# LPC43xx register map
File version: 10
CPU: CM4 r0p0, little endian, no MPU, no FPU, 3 interrupt priority bits
Registers are 32-bit, read-write, reset 0x0 unless marked. A register's access mark holds for its fields unless they carry their own. Offsets are from the block's base; [hi:lo] are bit positions; {n}, {i} and the like mark numbered series.

## SGPIO — Serial GPIO (SGPIO)
Base 0x40101000
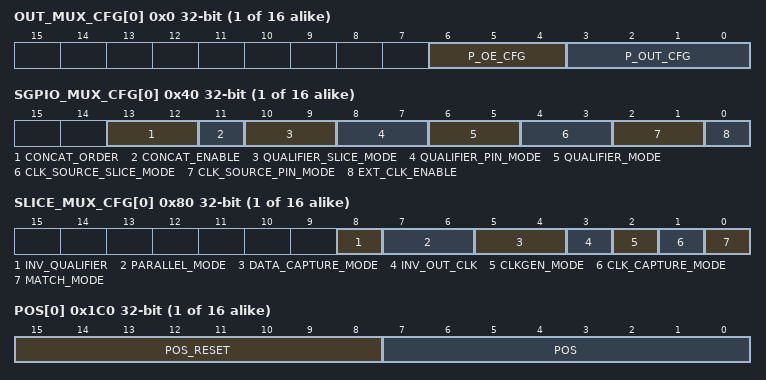
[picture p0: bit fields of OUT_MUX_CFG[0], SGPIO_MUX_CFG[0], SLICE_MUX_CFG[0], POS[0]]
{0x0+4i} OUT_MUX_CFG[{i}] (i=0..15) — Pin multiplexer configuration registers.
  [6:4] P_OE_CFG — Output enable source. All other values are reserved.
    0=GPIO_OE_STATE_SET_B (gpio_oe (state set by GPIO_OEREG)); 4=DOUT_OEM1_1_BIT_MOD (dout_oem1 (1-bit mode)); 5=DOUT_OEM2_2_BIT_MOD (dout_oem2 (2-bit mode)); 6=DOUT_OEM4_4_BIT_MOD (dout_oem4 (4-bit mode)); 7=DOUT_OEM8_8_BIT_MOD (dout_oem8 (8-bit mode))
  [3:0] P_OUT_CFG — Output control of output SGPIOn. All other values are reserved.
    0=DOUT_DOUTM1 (dout_doutm1 (1-bit mode)); 1=DOUT_DOUTM2A (dout_doutm2a (2-bit mode 2a)); 2=DOUT_DOUTM2B (dout_doutm2b (2-bit mode 2b)); 3=DOUT_DOUTM2C (dout_doutm2c (2-bit mode 2c)); 4=GPIO_OUT_LEVEL_SET (gpio_out (level set by GPIO_OUTREG)); 5=DOUT_DOUTM4A (dout_doutm4a (4-bit mode 4a)); 6=DOUT_DOUTM4B (dout_doutm4b (4-bit mode 4b)); 7=DOUT_DOUTM4C (dout_doutm4c (4-bit mode 4c)); 8=CLK_OUT; 9=DOUT_DOUTM8A (dout_doutm8a (8-bit mode 8a)); 10=DOUT_DOUTM8B (dout_doutm8b (8-bit mode 8b)); 11=DOUT_DOUTM8C (dout_doutm8c (8-bit mode 8c))
{0x40+4i} SGPIO_MUX_CFG[{i}] (i=0..15) — SGPIO multiplexer configuration registers.
  [13:12] CONCAT_ORDER — Select concatenation order
    0=SELF_LOOP; 1=2_SLICES; 2=4_SLICES; 3=8_SLICES
  [11] CONCAT_ENABLE — Enable concatenation.
    0=EXTERNAL_DATA_PIN; 1=CONCATENATE_DATA
  [10:9] QUALIFIER_SLICE_MODE — Select qualifier slice.
    0=SLICE_A (Slice A, but for slice A slice D is used.); 1=SLICE_H (Slice H, but for slice H slice O is used.); 2=SLICE_I (Slice I, but for slice I slice D is used.); 3=SLICE_P (Slice P, but for slice P slice O is used.)
  [8:7] QUALIFIER_PIN_MODE — Select qualifier pin.
    {v}=SGPIO{v+8} (v=0..3)
  [6:5] QUALIFIER_MODE — Select qualifier mode.
    0=ENABLE; 1=DISABLE; 2=SLICE_SEE_BITS_QUAL (Slice (see bits QUALIFIER_SLICE_MODE in this register)); 3=EXTERNAL_SGPIO_PIN (External SGPIO pin (SGPIO8, SGPIO9, SGPIO10, or SGPIO11))
  [4:3] CLK_SOURCE_SLICE_MODE — Select clock source slice. Note that slices D, H, O and P do not support this mode.
    0=SLICE_D; 1=SLICE_H; 2=SLICE_O; 3=SLICE_P
  [2:1] CLK_SOURCE_PIN_MODE — Select source clock pin.
    {v}=SGPIO{v+8} (v=0..3)
  [0] EXT_CLK_ENABLE — Select clock signal.
    0=INTERNAL_CLOCK_SIGNA (Internal clock signal (slice)); 1=EXTERNAL_CLOCK_SIGNA (External clock signal (pin))
{0x80+4i} SLICE_MUX_CFG[{i}] (i=0..15) — Slice multiplexer configuration registers.
  [8] INV_QUALIFIER — Inversion qualifier
    0=USE_NORMAL_QUALIFIER; 1=USE_INVERTED_QUALIFI (Use inverted qualifier.)
  [7:6] PARALLEL_MODE
    0=SHIFT_1_BIT_PER_CLOC (Shift 1 bit per clock.); 1=SHIFT_2_BITS_PER_CLO (Shift 2 bits per clock.); 2=SHIFT_4_BITS_PER_CLO (Shift 4 bits per clock.); 3=SHIFT_1_BYTE_PER_CLO (Shift 1 byte per clock.)
  [5:4] DATA_CAPTURE_MODE — Condition for input bit match interrupt
    0=DETECT_RISING_EDGE; 1=DETECT_FALLING_EDGE; 2=DETECT_LOW_LEVEL; 3=DETECT_HIGH_LEVEL
  [3] INV_OUT_CLK — Invert output clock
    0=NORMAL_CLOCK; 1=INVERTED_CLOCK
  [2] CLKGEN_MODE — Clock generation mode. Selects the clock generated by the slice counter or by an external pin or other slice as shift clock.
    0=USE_CLOCK_INTERNALLY (Use clock internally generated by COUNTER.); 1=USE_EXTERNAL_CLOCK_F (Use external clock from a pin or other slice.)
  [1] CLK_CAPTURE_MODE — Capture clock mode
    0=USE_RISING_CLOCK_EDG (Use rising clock edge.); 1=USE_FALLING_CLOCK_ED (Use falling clock edge.)
  [0] MATCH_MODE — Match mode. Selects whether the match filter is active or whether data is captured.
    0=DO_NOT_MATCH_DATA; 1=MATCH_DATA
{0xC0+4i} REG[{i}] (i=0..15) — Slice data registers. Each time COUNT0 reaches 0x0 the register shifts loading bit 31 with data captured from DIN(n). DOUT(n) is set to REG(0)
  [31:0] REG — At each active shift clock the register shifts right; loading REG(31) with data captured from DIN(n) and DOUT(n) is set to REG(0).
{0x100+4i} REG_SS[{i}] (i=0..15) — Slice data shadow registers. Each time POS reaches 0x0 the contents of REG_SS is exchanged with the content of REG
  [31:0] REG_SS — Each time POS reaches 0x0 the contents of REG_SS is exchanged with the content of REG.
{0x140+4i} PRESET[{i}] (i=0..15) — Reload value of COUNT0, loaded when COUNT0 reaches 0x0
  [11:0] PRESET — Counter reload value; loaded when COUNT reaches 0x0.
{0x180+4i} COUNT[{i}] (i=0..15) — Down counter, counts down each clock cycle.
  [11:0] COUNT — Down counter, counts down each shift clock cycle. Next count after 0x0 is PRESET.
{0x1C0+4i} POS[{i}] (i=0..15) — Each time COUNT0 reaches 0x0 POS counts down.
  [15:8] POS_RESET — Reload value for POS after POS reaches 0x0.
  [7:0] POS — Each time COUNT reaches 0x0 POS counts down.
0x200 MASK_A — Mask for pattern match function of slice A
  [31:0] MASK_A — Mask for pattern match function of slice A 0 = No effect. 1 = Mask this bit.
0x204 MASK_H — Mask for pattern match function of slice H
  [31:0] MASK_H — Mask for pattern match function of slice H 0 = No effect. 1 = Mask this bit.
0x208 MASK_I — Mask for pattern match function of slice I
  [31:0] MASK_I — Mask for pattern match function of slice I 0 = No effect . 1 = Mask this bit.
0x20C MASK_P — Mask for pattern match function of slice P
  [31:0] MASK_P — Mask for pattern match function of slice P 0 = No effect. 1 = Mask this bit.
0x210 GPIO_INREG ro — GPIO input status register
  [15:0] GPIO_INi — Bit i reflects the input state of SGPIO pin i . 0 = LOW 1 = HIGH
0x214 GPIO_OUTREG — GPIO output control register
  [15:0] GPIO_OUT — GPIO output register. Bit i sets the output of SGPIO pin i. 0 = LOW 1 = HIGH
0x218 GPIO_OENREG — GPIO OE control register
  [15:0] GPIO_OE — Bit i selects the output enable state of SGPIO pin i. 0 = GPIO output i is tri-stated . 1 = GPIO output i is active.
0x21C CTRL_ENABLE — Enables the slice COUNT counter
  [15:0] CTRL_EN — Slice count enable. Bit n controls slice n (0 = slice A, ..., 15 = slice P). 0 = Disables slice shift clock. 1 = Starts COUNTn or external shift clock.
0x220 CTRL_DISABLE — Disables the slice POS counter
  [15:0] CTRL_DIS — Slice count disable. Bit n controls slice n, (0 = slice A, ..., 15 = slice P). 0 = Enables COUNT and POS counters. The counters start counting when the CTRL_EN bit or bits are set in the CTRL_ENABLED register. 1 = Disables POS counter of slice n.
0xF00 CLR_EN_0 wo — Shift clock interrupt clear mask
  [15:0] CLR_SCI — 1 = Shift clock interrupt clear mask of slice n.
0xF04 SET_EN_0 wo — Shift clock interrupt set mask
  [15:0] SET_SCI — 1 = Shift clock interrupt set mask of slice n.
0xF08 ENABLE_0 ro — Shift clock interrupt enable
  [15:0] ENABLE_SCI — 1 = Shift clock interrupt enable of slice n.
0xF0C STATUS_0 ro — Shift clock interrupt status
  [15:0] STATUS_SCI — Shift clock interrupt status of slice n.
0xF10 CLR_STATUS_0 wo — Shift clock interrupt clear status
  [15:0] CLR_STATUS_SCI — Shift clock interrupt clear status of slice n.
0xF14 SET_STATUS_0 wo — Shift clock interrupt set status
  [15:0] SET_STATUS_SCI — Shift clock interrupt set status of slice n.
0xF20 CLR_EN_1 wo — Exchange clock interrupt clear mask
  [15:0] CLR_EN_CCI — 1 = Exchange clock interrupt clear mask of slice n.
0xF24 SET_EN_1 wo — Exchange clock interrupt set mask
  [15:0] SET_EN_CCI — 1 = Exchange clock interrupt set mask of slice n.
0xF28 ENABLE_1 ro — Exchange clock interrupt enable
  [15:0] ENABLE_CCI — Exchange clock interrupt enable of slice n.
0xF2C STATUS_1 ro — Exchange clock interrupt status
  [15:0] STATUS_CCI — Exchange clock interrupt status of slice n.
0xF30 CLR_STATUS_1 wo — Exchange clock interrupt clear status
  [15:0] CLR_STATUS_CCI — Exchange clock interrupt clear status of slice n.
0xF34 SET_STATUS_1 wo — Exchange clock interrupt set status
  [15:0] SET_STATUS_CCI — Exchange clock interrupt set status of slice n.
0xF40 CLR_EN_2 wo — Pattern match interrupt clear mask
  [15:0] CLR_EN2_PMI — 1 = Match interrupt clear mask of slice n.
0xF44 SET_EN_2 wo — Pattern match interrupt set mask
  [15:0] SET_EN_PMI — 1 = Match interrupt set mask of slice n.
0xF48 ENABLE_2 ro — Pattern match interrupt enable
  [15:0] ENABLE_PMI — Match interrupt enable of slice n.
0xF4C STATUS_2 ro — Pattern match interrupt status
  [15:0] STATUS_PMI — Match interrupt status of slice n.
0xF50 CLR_STATUS_2 wo — Pattern match interrupt clear status
  [15:0] CLR_STATUS_PMI — Match interrupt clear status of slice n.
0xF54 SET_STATUS_2 wo — Pattern match interrupt set status
  [15:0] SET_STATUS_PMI — Match interrupt set status of slice n.
0xF60 CLR_EN_3 wo — Input interrupt clear mask
  [15:0] CLR_EN_INPI — 1 = Input interrupt clear mask of slice n.
0xF64 SET_EN_3 wo — Input bit match interrupt set mask
  [15:0] SET_EN_INPI — 1 = Input interrupt set mask of slice n.
0xF68 ENABLE_3 ro — Input bit match interrupt enable
  [15:0] ENABLE3_INPI — Input interrupt enable of slice n.
0xF6C STATUS_3 ro — Input bit match interrupt status
  [15:0] STATUS_INPI — Input interrupt status of slice n.
0xF70 CLR_STATUS_3 wo — Input bit match interrupt clear status
  [15:0] CLR_STATUS_INPI — Input interrupt clear status of slice n.
0xF74 SET_STATUS_3 wo — Input bit match interrupt set status
  [15:0] SET_STATUS_INPI — Shift interrupt set status of slice n.
